# CC2340R5 register map
File version: 1.0
CPU: CM0P 1.0, other endian, MPU, FPU, 3 interrupt priority bits
Registers are 32-bit, read-write, reset 0x0 unless marked. A register's access mark holds for its fields unless they carry their own. Offsets are from the block's base; [hi:lo] are bit positions; {n}, {i} and the like mark numbered series.

## NVIC
Base 0xE000E000
0x100 ISER — Use the Interrupt Set-Enable Register to enable interrupts and determine which interrupts are currently enabled.
  [31:0] SETENA — [31:0] Writing 0 to a SETENA bit has no effect, writing 1 to a bit enables the corresponding interrupt. Reading the bit returns its current enable state. Reset clears the SETENA fields.
0x180 ICER — Use the Interrupt Clear-Enable Registers to disable interrupts and determine which interrupts are currently enabled.
  [31:0] CLRENA — [31:0] Writing 0 to a CLRENA bit has no effect, writing 1 to a bit disables the corresponding interrupt. Reading the bit returns its current enable state. Reset clears the CLRENA field.
0x200 ISPR — Use the Interrupt Set-Pending Register to force interrupts into the pending state and determine which interrupts are currently pending
  [31:0] SETPEND — [31:0] Interrupt set-pending bits for a: Write: 1 = pend interrupt 0 = no effect; Read: 1 = interrupt is pending 0 = interrupt is not pending.
0x280 ICPR — Use the Interrupt Clear-Pending Register to clear pending interrupts and determine which interrupts are currently pending.
  [31:0] CLRPEND — [31:0] Interrupt clear-pending bits: Write: 1 = clear interrupt pending bit, 0 = no effect; Read: 1 = interrupt is pending 0 = interrupt is not pending.
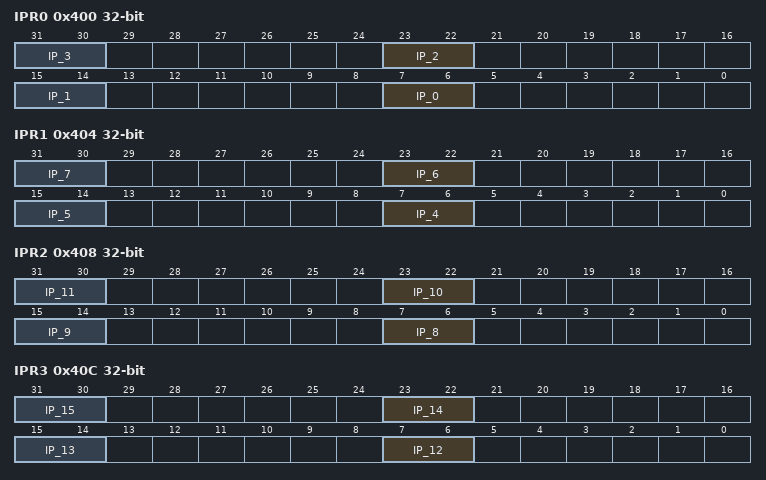
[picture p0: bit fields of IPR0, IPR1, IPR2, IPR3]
0x400 IPR0 — Use the Interrupt Priority Registers to assign a priority from 0 to 3 to each of the available interrupts. 0 is the highest priority, and 3 is the lowest.
  [8n+7:8n+6] IP_{n} (n=0..3) — [{8n+7}:{8n+6}] Priority of interrupt {n}
0x404 IPR1 — Use the Interrupt Priority Registers to assign a priority from 0 to 3 to each of the available interrupts. 0 is the highest priority, and 3 is the lowest.
  [8n-25:8n-26] IP_{n} (n=4..7) — [{8n-25}:{8n-26}] Priority of interrupt {n}
0x408 IPR2 — Use the Interrupt Priority Registers to assign a priority from 0 to 3 to each of the available interrupts. 0 is the highest priority, and 3 is the lowest.
  [8n-57:8n-58] IP_{n} (n=8..11) — [{8n-57}:{8n-58}] Priority of interrupt {n}
0x40C IPR3 — Use the Interrupt Priority Registers to assign a priority from 0 to 3 to each of the available interrupts. 0 is the highest priority, and 3 is the lowest.
  [8n-89:8n-90] IP_{n} (n=12..15) — [{8n-89}:{8n-90}] Priority of interrupt {n}
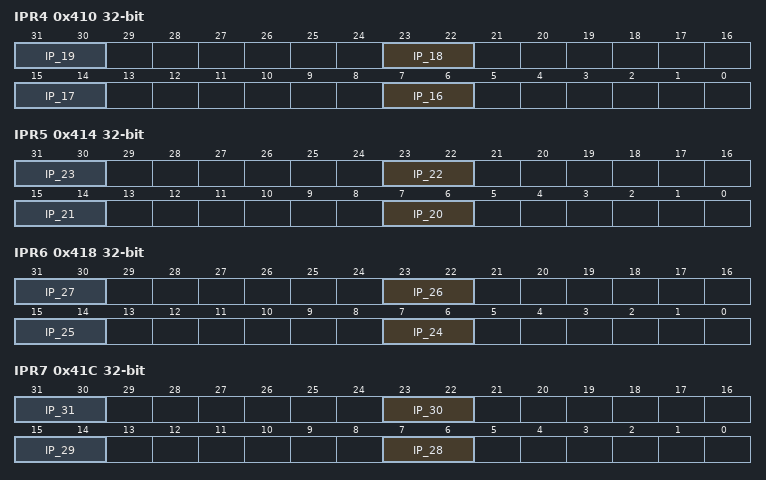
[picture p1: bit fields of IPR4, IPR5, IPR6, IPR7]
0x410 IPR4 — Use the Interrupt Priority Registers to assign a priority from 0 to 3 to each of the available interrupts. 0 is the highest priority, and 3 is the lowest.
  [8n-121:8n-122] IP_{n} (n=16..19) — [{8n-121}:{8n-122}] Priority of interrupt {n}
0x414 IPR5 — Use the Interrupt Priority Registers to assign a priority from 0 to 3 to each of the available interrupts. 0 is the highest priority, and 3 is the lowest.
  [8n-153:8n-154] IP_{n} (n=20..23) — [{8n-153}:{8n-154}] Priority of interrupt {n}
0x418 IPR6 — Use the Interrupt Priority Registers to assign a priority from 0 to 3 to each of the available interrupts. 0 is the highest priority, and 3 is the lowest.
  [8n-185:8n-186] IP_{n} (n=24..27) — [{8n-185}:{8n-186}] Priority of interrupt {n}
0x41C IPR7 — Use the Interrupt Priority Registers to assign a priority from 0 to 3 to each of the available interrupts. 0 is the highest priority, and 3 is the lowest.
  [8n-217:8n-218] IP_{n} (n=28..31) — [{8n-217}:{8n-218}] Priority of interrupt {n}

## SYSTICK
Base 0xE000E010
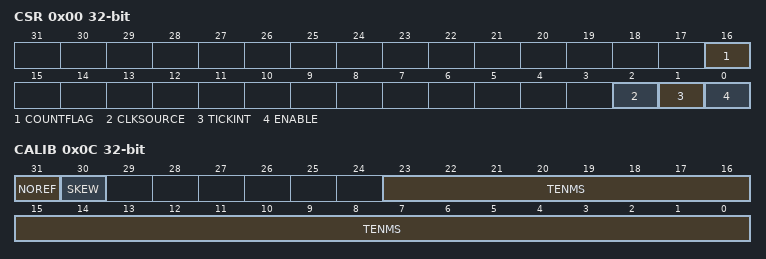
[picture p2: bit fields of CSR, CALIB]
0x00 CSR — Use the SysTick Control and Status Register to enable the SysTick features.
  [16] COUNTFLAG ro — [16:16] Returns 1 if timer counted to 0 since last time this was read. Clears on read by application or debugger.
  [2] CLKSOURCE ro — [2:2] SysTick clock source. Always reads as one if STCALIB reports NOREF. 0x0:Systick driven by external reference clock. 0x1:Systick driven by processor clock, hclk.
  [1] TICKINT — [1:1] 0x0:Counting down to zero does not pend the systick handler. software can use countflag to determine if the systick handler has ever counted to zero. 0x1:Counting down to zero pends the systick handler.
  [0] ENABLE — [0:0] Enable SysTick counter 0x0:Counter disabled 0x1:Counter operates in a multi-shot way. that is, counter loads with the reload value and then begins counting down. on reaching 0, it sets the countflag to 1 and optionally pends the systick handler, based on tickint. it then loads the reload value again, and begins counting.
0x04 RVR — Use the SysTick Reload Value Register to specify the start value to load into the current value register when the counter reaches 0. It can be any value between 0 and 0x00FFFFFF. A start value of 0 is possible, but has no effect because the SysTick interrupt and COUNTFLAG are activated when counting from 1 to 0. The reset value of this register is UNKNOWN.
  [23:0] RELOAD — [23:0] Value to load into the SysTick Current Value Register when the counter reaches 0.
0x08 CVR — Use the SysTick Current Value Register to find the current value in the register. The reset value of this register is UNKNOWN.
  [23:0] CURRENT — [23:0] Reads return the current value of the SysTick counter. This register is write-clear. Writing to it with any value clears the register to 0. Clearing this register also clears the COUNTFLAG bit of the SysTick Control and Status Register.
0x0C CALIB — Use the SysTick Calibration Value Register to enable software to scale to any required speed using divide and multiply.
  [31] NOREF ro — [31:31] If reads as 1, the Reference clock is not provided - the CLKSOURCE bit of the SysTick Control and Status register will be forced to 1 and cannot be cleared to 0.
  [30] SKEW ro — [30:30] If reads as 1, the calibration value for 10ms is inexact (due to clock frequency).
  [23:0] TENMS ro — [23:0] An optional Reload value to be used for 10ms (100Hz) timing, subject to system clock skew errors. If the value reads as 0, the calibration value is not known.

## SCSCS
Base 0xE000EFC0
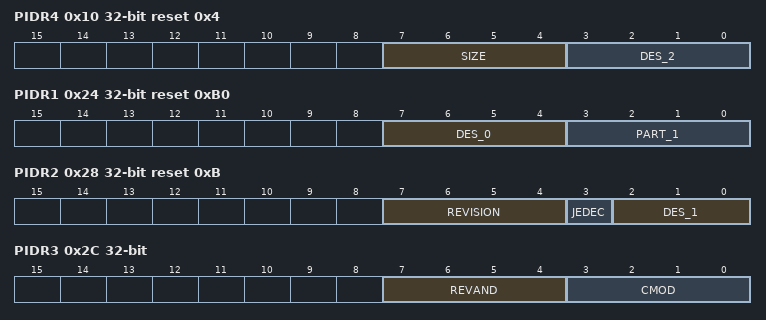
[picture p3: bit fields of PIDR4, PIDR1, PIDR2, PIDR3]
0x10 PIDR4 reset 0x4 — Part of the set of Peripheral Identification registers. Contains part of the designer identity and the memory footprint indicator.
  [7:4] SIZE ro — [7:4] This is a 4-bit value that indicates the total contiguous size of the memory window used by this component in powers of 2 from the standard 4KB. If a component only requires the standard 4KB then this should read as 0x0, 4KB only, for 8KB set to 0x1, 16KB == 0x2, 32KB == 0x3, and so on.
  [3:0] DES_2 ro — [3:0] Number of JEDEC continuation codes. Indicates the designer of the component (along with the identity code)
{0x0+4i} PIDR{i} (i=5..7) — Reserved
0x20 PIDR0 reset 0x8 — Part of the set of Peripheral Identification registers. Contains part of the designer specific part number.
  [7:0] PART_0 ro — [7:0] Bits [7:0] of the component's part number. This is selected by the designer of the component.
0x24 PIDR1 reset 0xB0 — Part of the set of Peripheral Identification registers. Contains part of the designer specific part number and part of the designer identity.
  [7:4] DES_0 ro — [7:4] Bits [3:0] of the JEDEC identity code indicating the designer of the component (along with the continuation code)
  [3:0] PART_1 ro — [3:0] Bits [11:8] of the component's part number. This is selected by the designer of the component.
0x28 PIDR2 reset 0xB — Part of the set of Peripheral Identification registers. Contains part of the designer identity and the product revision.
  [7:4] REVISION ro — [7:4] The Revision field is an incremental value starting at 0x0 for the first design of this component. This only increases by 1 for both major and minor revisions and is simply used as a look-up to establish the exact major/minor revision.
  [3] JEDEC ro — [3:3] Always set. Indicates that a JEDEC assigned value is used
  [2:0] DES_1 ro — [2:0] Bits [6:4] of the JEDEC identity code indicating the designer of the component (along with the continuation code)
0x2C PIDR3 — Part of the set of Peripheral Identification registers. Contains the RevAnd and Customer Modified fields.
  [7:4] REVAND ro — [7:4] This field indicates minor errata fixes specific to this design, for example metal fixes after implementation. In most cases this field is zero. It is recommended that component designers ensure this field can be changed by a metal fix if required, for example by driving it from registers that reset to zero.
  [3:0] CMOD ro — [3:0] Where the component is reusable IP, this value indicates if the customer has modified the behavior of the component. In most cases this field is zero.
0x30 CIDR0 reset 0xD — A component identification register, that indicates that the identification registers are present.
  [7:0] PRMBL_0 ro — [7:0] Contains bits [7:0] of the component identification
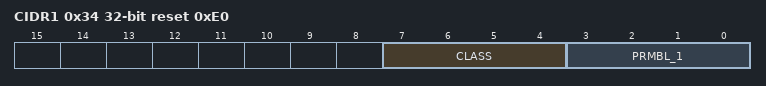
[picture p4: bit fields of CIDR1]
0x34 CIDR1 reset 0xE0 — A component identification register, that indicates that the identification registers are present. This register also indicates the component class.
  [7:4] CLASS ro — [7:4] Class of the component. E.g. ROM table, CoreSight component etc. Constitutes bits [15:12] of the component identification.
  [3:0] PRMBL_1 ro — [3:0] Contains bits [11:8] of the component identification
0x38 CIDR2 reset 0x5 — A component identification register, that indicates that the identification registers are present.
  [7:0] PRMBL_2 ro — [7:0] Contains bits [23:16] of the component identification
0x3C CIDR3 reset 0xB1 — A component identification register, that indicates that the identification registers are present.
  [7:0] PRMBL_3 ro — [7:0] Contains bits [31:24] of the component identification
